# ESP32-S31 register map
Vendor: ESPRESSIF SYSTEMS (SHANGHAI) CO., LTD.; Series: ESP32 S-Series; File version: 1
CPU: RV32IMAFC r0p0, little endian, no MPU, FPU, 0 interrupt priority bits
Address unit: 32 bits
Registers are 32-bit, read-write, reset 0x0 unless marked. A register's access mark holds for its fields unless they carry their own. Offsets are from the block's base; [hi:lo] are bit positions; lines under a group give offsets from that group.

## GMAC (part 2 of 6) — GMAC Peripheral
Base 0x20350000
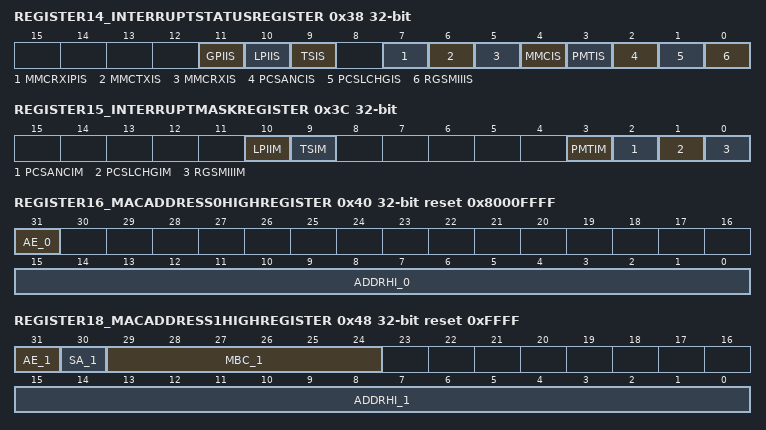
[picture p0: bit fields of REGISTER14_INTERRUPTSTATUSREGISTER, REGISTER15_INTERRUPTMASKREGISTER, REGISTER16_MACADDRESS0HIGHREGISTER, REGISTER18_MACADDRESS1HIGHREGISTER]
0x38 REGISTER14_INTERRUPTSTATUSREGISTER ro — Contains the interrupt status
  [11] GPIIS — GPI Interrupt Status When the GPIO feature is enabled, this bit is set when any active event _LL or LH_ occurs on the GPIS field _Bits [3:0]_ of Register 56 _General Purpose IO Register_ and the corresponding GPIE bit is enabled This bit is cleared on reading lane 0 _GPIS_ of Register 56 _General Purpose IO Register_ When the GPIO feature is not enabled, this bit is reserved
  [10] LPIIS — LPI Interrupt Status When the Energy Efficient Ethernet feature is enabled, this bit is set for any LPI state entry or exit in the MAC Transmitter or Receiver This bit is cleared on reading Bit 0 of Register 12 _LPI Control and Status Register_ In all other modes, this bit is reserved
  [9] TSIS — Timestamp Interrupt Status When the Advanced Timestamp feature is enabled, this bit is set when R_SS_RC any of the following conditions is true: The system time value equals or exceeds the value specified in the Target Time High and Low registers There is an overflow in the seconds register The Auxiliary snapshot trigger is asserted This bit is cleared on reading Bit 0 of Register 458 _Timestamp Status Register_ If default Timestamping is enabled, when set, this bit indicates that the system time value is equal to or exceeds the value specified in the Target Time registers In this mode, this bit is cleared after the completion of the read of this bit In all other modes, this bit is reserved
  [7] MMCRXIPIS — MMC Receive Checksum Offload Interrupt Status This bit is set high when an interrupt is generated in the MMC Receive Checksum Offload Interrupt Register This bit is cleared when all the bits in this interrupt register are cleared This bit is valid only when you select the optional MMC module and Checksum Offload Engine _Type 2_ during core configuration
  [6] MMCTXIS — MMC Transmit Interrupt Status This bit is set high when an interrupt is generated in the MMC Transmit Interrupt Register This bit is cleared when all the bits in this interrupt register are cleared This bit is valid only when you select the optional MMC module during core configuration
  [5] MMCRXIS — MMC Receive Interrupt Status This bit is set high when an interrupt is generated in the MMC Receive Interrupt Register This bit is cleared when all the bits in this interrupt register are cleared This bit is valid only when you select the optional MMC module during core configuration
  [4] MMCIS — MMC Interrupt Status This bit is set high when any of the Bits [7:5] is set high and cleared only when all of these bits are low This bit is valid only when you select the optional MMC module during core configuration
  [3] PMTIS — PMT Interrupt Status This bit is set when a magic packet or remote wakeup frame is received in the powerdown mode _see Bits 5 and 6 in the PMT Control and Status Register_ This bit is cleared when both Bits[6:5] are cleared because of a read operation to the PMT Control and Status register This bit is valid only when you select the optional PMT module during core configuration
  [2] PCSANCIS — PCS AutoNegotiation Complete This bit is set when the Autonegotiation is completed in the TBI, RTBI, or SGMII PHY interface _Bit 5 in Register 49 _AN Status Register__ This bit is cleared when you perform a read operation to the AN Status register This bit is valid only when you select the optional TBI, RTBI, or SGMII PHY interface during core configuration and operation
  [1] PCSLCHGIS — PCS Link Status Changed This bit is set because of any change in Link Status in the TBI, RTBI, or SGMII PHY interface _Bit 2 in Register 49 _AN Status Register__ This bit is cleared when you perform a read operation on the AN Status register This bit is valid only when you select the optional TBI, RTBI, or SGMII PHY interface during core configuration and operation
  [0] RGSMIIIS — RGMII or SMII Interrupt Status This bit is set because of any change in value of the Link Status of RGMII or SMII interface _Bit 3 in Register 54 _SGMII/RGMII/SMII Control and Status Register__ This bit is cleared when you perform a read operation on the SGMII/RGMII/SMII Control and Status Register This bit is valid only when you select the optional RGMII or SMII PHY interface during core configuration and operation
0x3C REGISTER15_INTERRUPTMASKREGISTER — Contains the masks for generating the interrupts
  [10] LPIIM — LPI Interrupt Mask When set, this bit disables the assertion of the interrupt signal because of the setting of the LPI Interrupt Status bit in Register 14 _Interrupt Status Register_ This bit is valid only when you select the Energy Efficient Ethernet feature during core configuration In all other modes, this bit is reserved
  [9] TSIM — Timestamp Interrupt Mask When set, this bit disables the assertion of the interrupt signal because of the setting of Timestamp Interrupt Status bit in Register 14 _Interrupt Status Register_ This bit is valid only when IEEE1588 timestamping is enabled In all other modes, this bit is reserved
  [3] PMTIM — PMT Interrupt Mask When set, this bit disables the assertion of the interrupt signal because of the setting of PMT Interrupt Status bit in Register 14 _Interrupt Status Register_
  [2] PCSANCIM — PCS AN Completion Interrupt Mask When set, this bit disables the assertion of the interrupt signal because of the setting of PCS Autonegotiation complete bit in Register 14 _Interrupt Status Register_
  [1] PCSLCHGIM — PCS Link Status Interrupt Mask When set, this bit disables the assertion of the interrupt signal because of the setting of the PCS Linkstatus changed bit in Register 14 _Interrupt Status Register_
  [0] RGSMIIIM — RGMII or SMII Interrupt Mask When set, this bit disables the assertion of the interrupt signal because of the setting of the RGMII or SMII Interrupt Status bit in Register 14 _Interrupt Status Register_
0x40 REGISTER16_MACADDRESS0HIGHREGISTER access per field reset 0x8000FFFF — Contains the higher 16 bits of the first MAC address
  [31] AE_0 ro — Address Enable This bit is always set to 1
  [15:0] ADDRHI_0 rw — MAC Address0 [47:32] This field contains the upper 16 bits _47:32_ of the first 6byte MAC address The MAC uses this field for filtering the received frames and inserting the MAC address in the Transmit Flow Control _Pause_ Frames
0x44 REGISTER17_MACADDRESS0LOWREGISTER reset 0xFFFFFFFF — Contains the lower 32 bits of the first MAC address
  [31:0] ADDRLO_0 — MAC Address0 [31:0] This field contains the lower 32 bits of the first 6byte MAC address This is used by the MAC for filtering the received frames and inserting the MAC address in the Transmit Flow Control _Pause_ Frames
0x48 REGISTER18_MACADDRESS1HIGHREGISTER reset 0xFFFF — Contains the higher 16 bits of the second MAC address This register is present only when Enable MAC Address1 is selected in coreConsultant _See Table 78_
  [31] AE_1 — Address Enable
  [30] SA_1 — Source Address When this bit is set, the MAC Address1[47:0] is used to compare with the SA fields of the received frame When this bit is reset, the MAC Address1[47:0] is used to compare with the DA fields of the received frame
  [29:24] MBC_1 — Mask Byte Control These bits are mask control bits for comparison of each of the MAC Address bytes When set high, the MAC does not compare the corresponding byte of received DA or SA with the contents of MAC Address1 registers Each bit controls the masking of the bytes as follows: Bit 29: Register 18[15:8] Bit 28: Register 18[7:0] Bit 27: Register 19[31:24] Bit 24: Register 19[7:0] You can filter a group of addresses _known as group address filtering_ by masking one or more bytes of the address
  [15:0] ADDRHI_1 — MAC Address1 [47:32] This field contains the upper 16 bits _47:32_ of the second 6byte MAC address
0x4C REGISTER19_MACADDRESS1LOWREGISTER reset 0xFFFFFFFF — Contains the lower 32 bits of the second MAC address This register is present only when Enable MAC Address1 is selected in coreConsultant _See Table 78_
  [31:0] ADDRLO_1 — MAC Address1 [31:0] This field contains the lower 32 bits of the second 6byte MAC address The content of this field is undefined until loaded by the Application after the initialization process
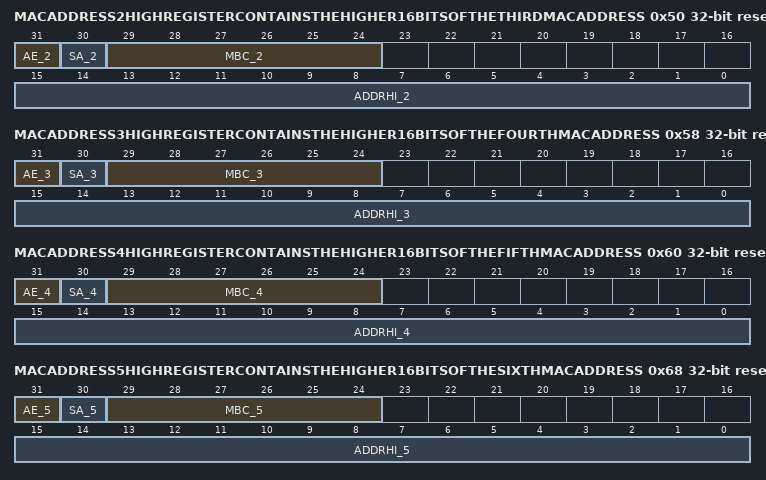
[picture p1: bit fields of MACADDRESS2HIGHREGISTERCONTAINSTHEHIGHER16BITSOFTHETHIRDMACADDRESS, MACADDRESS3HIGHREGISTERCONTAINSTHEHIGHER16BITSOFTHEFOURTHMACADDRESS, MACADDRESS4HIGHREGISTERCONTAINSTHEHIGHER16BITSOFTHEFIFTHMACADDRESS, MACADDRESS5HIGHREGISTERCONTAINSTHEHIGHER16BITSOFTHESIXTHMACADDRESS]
0x50 MACADDRESS2HIGHREGISTERCONTAINSTHEHIGHER16BITSOFTHETHIRDMACADDRESS reset 0xFFFF — Reserved
  [31] AE_2 — This register is present only when Enable MAC Address2 is selected in coreConsultant _See Table 78_
  [30] SA_2 — This register is present only when Enable MAC Address2 is selected in coreConsultant _See Table 78_
  [29:24] MBC_2 — This register is present only when Enable MAC Address2 is selected in coreConsultant _See Table 78_
  [15:0] ADDRHI_2 — This register is present only when Enable MAC Address2 is selected in coreConsultant _See Table 78_
0x54 MACADDRESS2LOWREGISTERCONTAINSTHELOWER32BITSOFTHETHIRDMACADDRESS reset 0xFFFFFFFF — Reserved
  [31:0] ADDRLO_2 — This register is present only when Enable MAC Address2 is selected in coreConsultant _See Table 78_
0x58 MACADDRESS3HIGHREGISTERCONTAINSTHEHIGHER16BITSOFTHEFOURTHMACADDRESS reset 0xFFFF — Reserved
  [31] AE_3 — This register is present only when Enable MAC Address3 is selected in coreConsultant _See Table 78_
  [30] SA_3 — This register is present only when Enable MAC Address3 is selected in coreConsultant _See Table 78_
  [29:24] MBC_3 — This register is present only when Enable MAC Address3 is selected in coreConsultant _See Table 78_
  [15:0] ADDRHI_3 — This register is present only when Enable MAC Address3 is selected in coreConsultant _See Table 78_
0x5C MACADDRESS3LOWREGISTERCONTAINSTHELOWER32BITSOFTHEFOURTHMACADDRESS reset 0xFFFFFFFF — Reserved
  [31:0] ADDRLO_3 — This register is present only when Enable MAC Address3 is selected in coreConsultant _See Table 78_
0x60 MACADDRESS4HIGHREGISTERCONTAINSTHEHIGHER16BITSOFTHEFIFTHMACADDRESS reset 0xFFFF — Reserved
  [31] AE_4 — This register is present only when Enable MAC Address4 is selected in coreConsultant _See Table 78_
  [30] SA_4 — This register is present only when Enable MAC Address4 is selected in coreConsultant _See Table 78_
  [29:24] MBC_4 — This register is present only when Enable MAC Address4 is selected in coreConsultant _See Table 78_
  [15:0] ADDRHI_4 — This register is present only when Enable MAC Address4 is selected in coreConsultant _See Table 78_
0x64 MACADDRESS4LOWREGISTERCONTAINSTHELOWER32BITSOFTHEFIFTHMACADDRESS reset 0xFFFFFFFF — Reserved
  [31:0] ADDRLO_4 — This register is present only when Enable MAC Address4 is selected in coreConsultant _See Table 78_
0x68 MACADDRESS5HIGHREGISTERCONTAINSTHEHIGHER16BITSOFTHESIXTHMACADDRESS reset 0xFFFF — Reserved
  [31] AE_5 — This register is present only when Enable MAC Address5 is selected in coreConsultant _See Table 78_
  [30] SA_5 — This register is present only when Enable MAC Address5 is selected in coreConsultant _See Table 78_
  [29:24] MBC_5 — This register is present only when Enable MAC Address5 is selected in coreConsultant _See Table 78_
  [15:0] ADDRHI_5 — This register is present only when Enable MAC Address5 is selected in coreConsultant _See Table 78_
0x6C MACADDRESS5LOWREGISTERCONTAINSTHELOWER32BITSOFTHESIXTHMACADDRESS reset 0xFFFFFFFF — Reserved
  [31:0] ADDRLO_5 — This register is present only when Enable MAC Address5 is selected in coreConsultant _See Table 78_
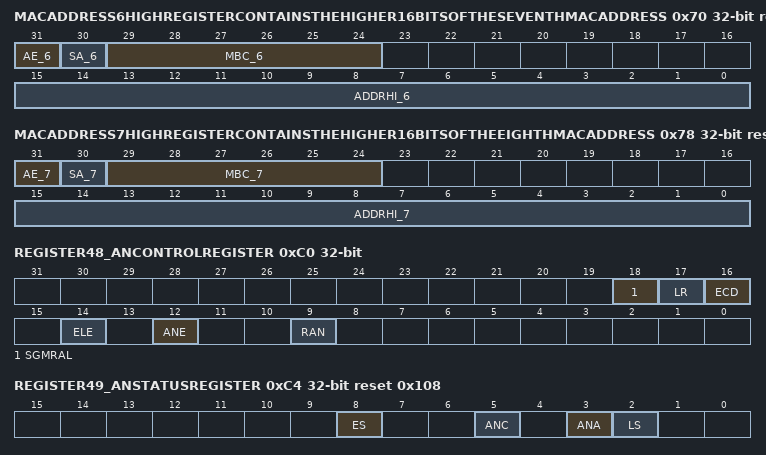
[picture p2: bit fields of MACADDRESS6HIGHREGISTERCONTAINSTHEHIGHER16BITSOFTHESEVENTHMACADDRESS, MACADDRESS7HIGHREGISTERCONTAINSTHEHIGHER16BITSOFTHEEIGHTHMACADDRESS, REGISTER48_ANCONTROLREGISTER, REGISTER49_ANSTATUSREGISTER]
0x70 MACADDRESS6HIGHREGISTERCONTAINSTHEHIGHER16BITSOFTHESEVENTHMACADDRESS reset 0xFFFF — Reserved
  [31] AE_6 — This register is present only when Enable MAC Address6 is selected in coreConsultant _See Table 78_
  [30] SA_6 — This register is present only when Enable MAC Address6 is selected in coreConsultant _See Table 78_
  [29:24] MBC_6 — This register is present only when Enable MAC Address6 is selected in coreConsultant _See Table 78_
  [15:0] ADDRHI_6 — This register is present only when Enable MAC Address6 is selected in coreConsultant _See Table 78_
0x74 MACADDRESS6LOWREGISTERCONTAINSTHELOWER32BITSOFTHESEVENTHMACADDRESS reset 0xFFFFFFFF — Reserved
  [31:0] ADDRLO_6 — This register is present only when Enable MAC Address6 is selected in coreConsultant _See Table 78_
0x78 MACADDRESS7HIGHREGISTERCONTAINSTHEHIGHER16BITSOFTHEEIGHTHMACADDRESS reset 0xFFFF — Reserved
  [31] AE_7 — This register is present only when Enable MAC Address7 is selected in coreConsultant _See Table 78_
  [30] SA_7 — This register is present only when Enable MAC Address7 is selected in coreConsultant _See Table 78_
  [29:24] MBC_7 — This register is present only when Enable MAC Address7 is selected in coreConsultant _See Table 78_
  [15:0] ADDRHI_7 — This register is present only when Enable MAC Address7 is selected in coreConsultant _See Table 78_
0x7C MACADDRESS7LOWREGISTERCONTAINSTHELOWER32BITSOFTHEEIGHTHMACADDRESS reset 0xFFFFFFFF — Reserved
  [31:0] ADDRLO_7 — This register is present only when Enable MAC Address7 is selected in coreConsultant _See Table 78_
0xC0 REGISTER48_ANCONTROLREGISTER — Enables and/or restarts autonegotiation This register also enables the Physical Coding Sublayer _PCS_ loopback This register is present only when you select the TBI, RTBI, or SGMII interface in coreConsultant
  [18] SGMRAL — SGMII RAL Control When set, this bit forces the SGMII RAL block to operate in the speed configured in the Speed and Port Select bits of the MAC Configuration register This is useful when the SGMII interface is used in a direct MAC to MAC connection _without a PHY_ and any MAC must reconfigure the speed When reset, the SGMII RAL block operates according to the link speed status received on SGMII _from the PHY_ This bit is reserved _and RO_ if the SGMII PHY interface is not selected during core configuration
  [17] LR — Lock to Reference When set, this bit enables the PHY to lock its PLL to the 125 MHz reference clock This bit controls the pcs_lck_ref_o signal on the TBI, RTBI, or SGMII interface
  [16] ECD — Enable Comma Detect When set, this bit enables the PHY for comma detection and word resynchronization This bit controls the pcs_en_cdet_o signal on the TBI, RTBI, or SGMII interface
  [14] ELE — External Loopback Enable When set, this bit causes the PHY to loopback the transmit data into the receive path The pcs_ewrap_o signal is asserted high when this bit is set
  [12] ANE — AutoNegotiation Enable When set, this bit enables the MAC to perform autonegotiation with the link partner Clearing this bit disables the autonegotiation
  [9] RAN — Restart AutoNegotiation When set, this bit causes autonegotiation to restart if Bit 12 _ANE_ is set This bit is selfclearing after autonegotiation starts This bit should be cleared for normal operation
0xC4 REGISTER49_ANSTATUSREGISTER ro reset 0x108 — Indicates the link and autonegotiation status This register is present only when you select the TBI, RTBI, or SGMII interface in coreConsultant
  [8] ES — Extended Status This bit is tied to high if the TBI or RTBI interface is selected during core configuration indicating that the MAC supports extended status information in Register 53 _TBI Extended Status Register_ This bit is tied to low if the SGMII interface is selected and the TBI or RTBI interface is not selected during core configuration indicating that Register 53 is not present
  [5] ANC — AutoNegotiation Complete When set, this bit indicates that the autonegotiation process is complete This bit is cleared when autonegotiation is reinitiated
  [3] ANA — AutoNegotiation Ability This bit is always high because the MAC supports auto negotiation
  [2] LS — Link Status This bit indicates whether the data channel _link_ is up or down For the TBI, RTBI or SGMII interfaces, if ANEG is going on, data cannot be transferred across the link and hence the link is given as down
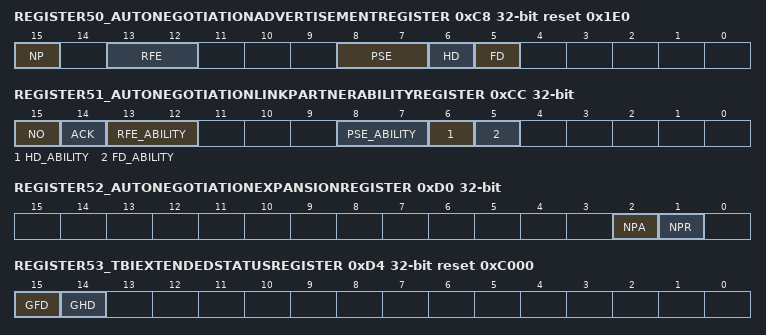
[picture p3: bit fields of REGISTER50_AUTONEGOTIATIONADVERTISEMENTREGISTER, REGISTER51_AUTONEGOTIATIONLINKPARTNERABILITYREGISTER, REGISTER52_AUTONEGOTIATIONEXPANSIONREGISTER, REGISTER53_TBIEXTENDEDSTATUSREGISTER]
0xC8 REGISTER50_AUTONEGOTIATIONADVERTISEMENTREGISTER access per field reset 0x1E0 — This register is configured before autonegotiation begins It contains the advertised ability of the MAC This register is present only when you select the TBI or RTBI interface in coreConsultant
  [15] NP ro — Next Page Support This bit is always low because the MAC does not support the next page
  [13:12] RFE rw — Remote Fault Encoding These bits provide a remote fault encoding, indicating to a link partner that a fault or error condition has occurred The encoding of these bits is defined in IEEE 8023z, Section 37215
  [8:7] PSE rw — Pause Encoding These bits provide an encoding for the Pause bits, indicating that the MAC is capable of configuring the Pause function as defined in IEEE 8023x The encoding of these bits is defined in IEEE 8023z, Section 37214
  [6] HD rw — HalfDuplex When set high, this bit indicates that the MAC supports the halfduplex mode This bit is always low _and RO_ when the MAC is configured for the fullduplexonly mode
  [5] FD rw — FullDuplex When set high, this bit indicates that the MAC supports the fullduplex mode
0xCC REGISTER51_AUTONEGOTIATIONLINKPARTNERABILITYREGISTER ro — Contains the advertised ability of the link partner Its value is valid after successful completion of autonegotiation or when a new base page has been received _indicated in the AutoNegotiation Expansion Register_ This register is present only when you select the TBI or RTBI interface in coreConsultant
  [15] NO — Next Page Support When set, this bit indicates that more next page information is available When cleared, this bit indicates that next page exchange is not desired
  [14] ACK — Acknowledge When set, the autonegotiation function uses this bit to indicate that the link partner has successfully received the base page of the MAC When cleared, it indicates that the link partner did not successfully receive the base page of the MAC
  [13:12] RFE_ABILITY — Remote Fault Encoding These bits provide a remote fault encoding, indicating a fault or error condition of the link partner The encoding of these bits is defined in IEEE 8023z, Section 37215
  [8:7] PSE_ABILITY — Pause Encoding These bits provide an encoding for the Pause bits, indicating that the link partner's capability of configuring the Pause function as defined in the IEEE 8023x specification The encoding of these bits is defined in IEEE 8023z, Section 37214
  [6] HD_ABILITY — HalfDuplex When set, this bit indicates that the link partner has the ability to operate in the halfduplex mode When cleared, this bit indicates that the link partner does not have the ability to operate in the halfduplex mode
  [5] FD_ABILITY — FullDuplex When set, this bit indicates that the link partner has the ability to operate in the full duplex mode When cleared, this bit indicates that the link partner does not have the ability to operate in the fullduplex mode
0xD0 REGISTER52_AUTONEGOTIATIONEXPANSIONREGISTER ro — Indicates whether a new base page has been received from the link partner This register is present only when you select the TBI or RTBI interface in coreConsultant
  [2] NPA — Next Page Ability This bit is always low because the MAC does not support the next page function
  [1] NPR — New Page Received When set, this bit indicates that the MAC has received a new page This bit is cleared when read
0xD4 REGISTER53_TBIEXTENDEDSTATUSREGISTER ro reset 0xC000 — Indicates all modes of operation of the MAC This register is present only when you select the TBI or RTBI interface in coreConsultant
  [15] GFD — 1000BASEX FullDuplex Capable This bit indicates that the MAC is able to perform the fullduplex and 1000BASEX operations
  [14] GHD — 1000BASEX HalfDuplex Capable This bit indicates that the MAC is able to perform the halfduplex and 1000BASEX operations This bit is always low when the MAC is configured for the fullduplexonly operation during core configuration
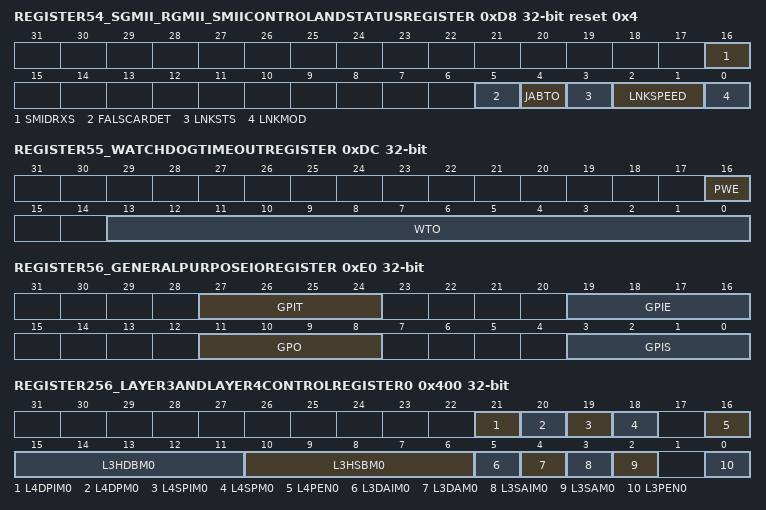
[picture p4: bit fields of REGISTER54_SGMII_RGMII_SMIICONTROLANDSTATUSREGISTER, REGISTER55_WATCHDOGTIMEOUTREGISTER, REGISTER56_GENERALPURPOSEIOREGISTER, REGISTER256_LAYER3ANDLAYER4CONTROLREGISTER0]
0xD8 REGISTER54_SGMII_RGMII_SMIICONTROLANDSTATUSREGISTER access per field reset 0x4 — Indicates the status signals received from the PHY through the SGMII, RGMII, or SMII interface This register is present only when you select the SGMII, RGMII, or SMII interface in coreConsultant
  [16] SMIDRXS rw — Delay SMII RX Data Sampling with respect to the SMII SYNC Signal When set, the first bit of the SMII RX data is sampled one cycle after the SMII SYNC signal When reset, the first bit of the SMII RX data is sampled along with the SMII SYNC signal If the SMII PHY Interface with source synchronous mode is selected during core configuration, this bit is reserved _RO with default value_
  [5] FALSCARDET ro — False Carrier Detected This bit indicates whether the SMII PHY detected false carrier _1'b1_ This bit is reserved when the MAC is configured for the SGMII or RGMII PHY interface
  [4] JABTO ro — Jabber Timeout This bit indicates whether there is jabber timeout error _1'b1_ in the received frame This bit is reserved when the MAC is configured for the SGMII or RGMII PHY interface
  [3] LNKSTS ro — Link Status This bit indicates whether the link between the local PHY and the remote PHY is up or down It gives the status of the link between the SGMII of MAC and the SGMII of the local PHY The status bits are received from the local PHY during ANEG betweent he MAC and PHY on the SGMII link
  [2:1] LNKSPEED ro — Link Speed
  [0] LNKMOD ro — Link Mode This bit indicates the current mode of operation of the link: 1’b0: Halfduplex mode 1’b1: Fullduplex mode
0xDC REGISTER55_WATCHDOGTIMEOUTREGISTER — Controls the watchdog timeout for received frames
  [16] PWE — Programmable Watchdog Enable When this bit is set and Bit 23 _WD_ of Register 0 _MAC Configuration Register_ is reset, the WTO field _Bits[13:0]_ is used as watchdog timeout for a received frame When this bit is cleared, the watchdog timeout for a received frame is controlled by the setting of Bit 23 _WD_ and Bit 20 _JE_ in Register 0 _MAC Configuration Register_
  [13:0] WTO — Watchdog Timeout When Bit 16 _PWE_ is set and Bit 23 _WD_ of Register 0 _MAC Configuration Register_ is reset, this field is used as watchdog timeout for a received frame If the length of a received frame exceeds the value of this field, such frame is terminated and declared as an error frame Note: When Bit 16 _PWE_ is set, the value in this field should be more than 1,522 _0x05F2_ Otherwise, the IEEE Std 8023specified valid tagged frames are declared as error frames and are dropped
0xE0 REGISTER56_GENERALPURPOSEIOREGISTER — Provides the control to drive up to 4 bits of output ports _GPO_ and also provides the status of up to 4 input ports _GPIS_
  [27:24] GPIT — GPI Type When set, this bit indicates that the corresponding GPIS is of latchedlow _LL_ type When reset, this bit indicates that the corresponding GPIS is of latchedhigh _LH_ type The number of bits available in this field depend on the GP Input Signal Width option Other bits are not used _reserved and always reset_
  [19:16] GPIE — GPI Interrupt Enable When this bit is set and the programmed event _LL or LH_ occurs on the corresponding GPIS bit, Bit 11 _GPIIS_ of Register 14 _Interrupt Status Register_ is set Accordingly, the interrupt is generated on the mci_intr_o or sbd_intr_o The GPIIS bit is cleared when the host reads the Bits[7:0] of this register When reset, Bit 11 _GPIIS_ of Register 14 _Interrupt Status Register_ is not set when any event occurs on the corresponding GPIS bits The number of bits available in this field depend on the GP Input Signal Width option Other bits are not used _reserved and always reset_
  [11:8] GPO — General Purpose Output When this bit is set, it directly drives the gpo_o output ports When this bit is reset, it does not directly drive the gpo_o output ports The number of bits available in this field depend on the GP Output Signal Width option Other bits are not used _reserved and always reset_
  [3:0] GPIS — General Purpose Input Status This field gives the status of the signals connected to the gpi_i input ports This field is of the following types based on the setting of the corresponding GPIT field of this register: Latchedlow _LL_: This field is cleared when the corresponding gpi_i input becomes low This field remains low until the host reads this field After this, this field reflects the current value of the gpi_i input Latchedhigh _LH_: This field is set when the corresponding gpi_i input becomes high This field remains high until the host reads this field After this, this field reflects the current value of the gpi_i input The number of bits available in this field depend on the GP Input Signal Width option Other bits are not used _reserved and always reset_
0x400 REGISTER256_LAYER3ANDLAYER4CONTROLREGISTER0 — Controls the operations of the Layer 3 and Layer 4 frame filtering
  [21] L4DPIM0 — Layer 4 Destination Port Inverse Match Enable When set, this bit indicates that the Layer 4 Destination Port number field is enabled for inverse matching When reset, this bit indicates that the Layer 4 Destination Port number field is enabled for perfect matching This bit is valid and applicable only when Bit 20 _L4DPM0_ is set high
  [20] L4DPM0 — Layer 4 Destination Port Match Enable When set, this bit indicates that the Layer 4 Destination Port number field is enabled for matching When reset, the MAC ignores the Layer 4 Destination Port number field for matching
  [19] L4SPIM0 — Layer 4 Source Port Inverse Match Enable When set, this bit indicates that the Layer 4 Source Port number field is enabled for inverse matching When reset, this bit indicates that the Layer 4 Source Port number field is enabled for perfect matching This bit is valid and applicable only when Bit 18 _L4SPM0_ is set high
  [18] L4SPM0 — Layer 4 Source Port Match Enable When set, this bit indicates that the Layer 4 Source Port number field is enabled for matching When reset, the MAC ignores the Layer 4 Source Port number field for matching
  [16] L4PEN0 — Layer 4 Protocol Enable When set, this bit indicates that the Source and Destination Port number fields for UDP frames are used for matching When reset, this bit indicates that the Source and Destination Port number fields for TCP frames are used for matching The Layer 4 matching is done only when either L4SPM0 or L4DPM0 bit is set high
  [15:11] L3HDBM0 — Layer 3 IP DA Higher Bits Match IPv4 Frames: This field contains the number of higher bits of IP Destination Address that are matched in the IPv4 frames The following list describes the values of this field: 0: No bits are masked 1: LSb[0] is masked 2: Two LSbs [1:0] are masked 31: All bits except MSb are masked IPv6 Frames: Bits [12:11] of this field correspond to Bits [6:5] of L3HSBM0, which indicate the number of lower bits of IP Source or Destination Address that are masked in the IPv6 frames The following list describes the concatenated values of the L3HDBM0[1:0] and L3HSBM0 bits: 0: No bits are masked 1: LSb[0] is masked 2: Two LSbs [1:0] are masked … 127: All bits except MSb are masked This field is valid and applicable only if L3DAM0 or L3SAM0 is set high
  [10:6] L3HSBM0 — Layer 3 IP SA Higher Bits Match IPv4 Frames: This field contains the number of lower bits of IP Source Address that are masked for matching in the IPv4 frames The following list describes the values of this field: 0: No bits are masked 1: LSb[0] is masked 2: Two LSbs [1:0] are masked 31: All bits except MSb are masked IPv6 Frames: This field contains Bits [4:0] of the field that indicates the number of higher bits of IP Source or Destination Address matched in the IPv6 frames This field is valid and applicable only if L3DAM0 or L3SAM0 is set high
  [5] L3DAIM0 — Layer 3 IP DA Inverse Match Enable When set, this bit indicates that the Layer 3 IP Destination Address field is enabled for inverse matching When reset, this bit indicates that the Layer 3 IP Destination Address field is enabled for perfect matching This bit is valid and applicable only when Bit 4 _L3DAM0_ is set high
  [4] L3DAM0 — Layer 3 IP DA Match Enable When set, this bit indicates that Layer 3 IP Destination Address field is enabled for matching When reset, the MAC ignores the Layer 3 IP Destination Address field for matching Note: When Bit 0 _L3PEN0_ is set, you should set either this bit or Bit 2 _L3SAM0_ because either IPv6 DA or SA can be checked for filtering
  [3] L3SAIM0 — Layer 3 IP SA Inverse Match Enable When set, this bit indicates that the Layer 3 IP Source Address field is enabled for inverse matching When reset, this bit indicates that the Layer 3 IP Source Address field is enabled for perfect matching This bit is valid and applicable only when Bit 2 _L3SAM0_ is set high
  [2] L3SAM0 — Layer 3 IP SA Match Enable When set, this bit indicates that the Layer 3 IP Source Address field is enabled for matching When reset, the MAC ignores the Layer 3 IP Source Address field for matching Note: When Bit 0 _L3PEN0_ is set, you should set either this bit or Bit 4 _L3DAM0_ because either IPv6 SA or DA can be checked for filtering
  [0] L3PEN0 — Layer 3 Protocol Enable When set, this bit indicates that the Layer 3 IP Source or Destination Address matching is enabled for the IPv6 frames When reset, this bit indicates that the Layer 3 IP Source or Destination Address matching is enabled for the IPv4 frames The Layer 3 matching is done only when either L3SAM0 or L3DAM0 bit is set high
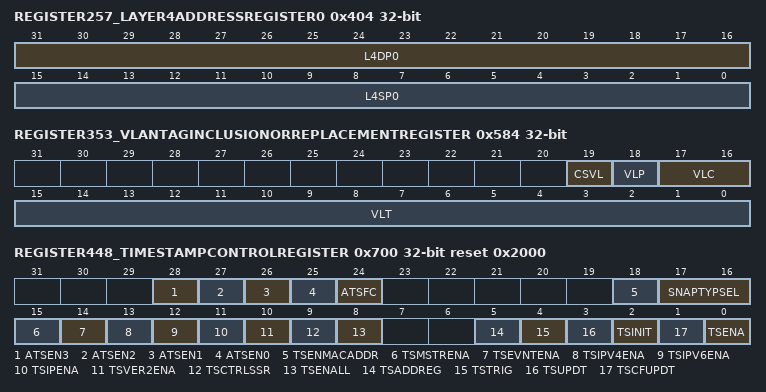
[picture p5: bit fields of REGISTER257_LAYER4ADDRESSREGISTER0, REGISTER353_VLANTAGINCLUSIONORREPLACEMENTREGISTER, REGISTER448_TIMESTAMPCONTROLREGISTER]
0x404 REGISTER257_LAYER4ADDRESSREGISTER0 — Layer 4 Port number field It contains the 16bit Source and Destination Port numbers of the TCP or UDP frame
  [31:16] L4DP0 — Layer 4 Destination Port Number Field When Bit 16 _L4PEN0_ is reset and Bit 20 _L4DPM0_ is set in Register 256 _Layer 3 and Layer 4 Control Register 0_, this field contains the value to be matched with the TCP Destination Port Number field in the IPv4 or IPv6 frames When Bit 16 _L4PEN0_ and Bit 20 _L4DPM0_ are set in Register 256 _Layer 3 and Layer 4 Control Register 0_, this field contains the value to be matched with the UDP Destination Port Number field in the IPv4 or IPv6 frames
  [15:0] L4SP0 — Layer 4 Source Port Number Field When Bit 16 _L4PEN0_ is reset and Bit 20 _L4DPM0_ is set in Register 256 _Layer 3 and Layer 4 Control Register 0_, this field contains the value to be matched with the TCP Source Port Number field in the IPv4 or IPv6 frames When Bit 16 _L4PEN0_ and Bit 20 _L4DPM0_ are set in Register 256 _Layer 3 and Layer 4 Control Register 0_, this field contains the value to be matched with the UDP Source Port Number field in the IPv4 or IPv6 frames
0x410 REGISTER260_LAYER3ADDRESS0REGISTER0 — Layer 3 Address field For IPv4 frames, it contains the 32bit IP Source Address field For IPv6 frames, it contains Bits [31:0] of the 128bit IP Source Address or Destination Address field
  [31:0] L3A00 — Layer 3 Address 0 Field When Bit 0 _L3PEN0_ and Bit 2 _L3SAM0_ are set in Register 256 _Layer 3 and Layer 4 Control Register 0_, this field contains the value to be matched with Bits [31:0] of the IP Source Address field in the IPv6 frames When Bit 0 _L3PEN0_ and Bit 4 _L3DAM0_ are set in Register 256 _Layer 3 and Layer 4 Control Register 0_, this field contains the value to be matched with Bits [31:0] of the IP Destination Address field in the IPv6 frames When Bit 0 _L3PEN0_ is reset and Bit 2 _L3SAM0_ is set in Register 256 _Layer 3 and Layer 4 Control Register 0_, this field contains the value to be matched with the IP Source Address field in the IPv4 frames
0x414 REGISTER261_LAYER3ADDRESS1REGISTER0 — Layer 3 Address 1 field For IPv4 frames, it contains the 32bit IP Destination Address field For IPv6 frames, it contains Bits [63:32] of the 128bit IP Source Address or Destination Address field
  [31:0] L3A10 — Layer 3 Address 1 Field When Bit 0 _L3PEN0_ and Bit 2 _L3SAM0_ are set in Register 256 _Layer 3 and Layer 4 Control Register 0_, this field contains the value to be matched with Bits [63:32] of the IP Source Address field in the IPv6 frames When Bit 0 _L3PEN0_ and Bit 4 _L3DAM0_ are set in Register 256 _Layer 3 and Layer 4 Control Register 0_, this field contains the value to be matched with Bits [63:32] of the IP Destination Address field in the IPv6 frames When Bit 0 _L3PEN0_ is reset and Bit 4 _L3DAM0_ is set in Register 256 _Layer 3 and Layer 4 Control Register 0_, this field contains the value to be matched with the IP Destination Address field in the IPv4 frames
0x418 REGISTER262_LAYER3ADDRESS2REGISTER0 — Layer 3 Address 2 field This register is reserved for IPv4 frames For IPv6 frames, it contains Bits [95:64] of the 128bit IP Source Address or Destination Address field
  [31:0] L3A20 — Layer 3 Address 2 Field When Bit 0 _L3PEN0_ and Bit 2 _L3SAM0_ are set in Register 256 _Layer 3 and Layer 4 Control Register 0_, this field contains the value to be matched with Bits [95:64] of the IP Source Address field in the IPv6 frames When Bit 0 _L3PEN0_ and Bit 4 _L3DAM0_ are set in Register 256 _Layer 3 and Layer 4 Control Register 0_, this field contains value to be matched with Bits [95:64] of the IP Destination Address field in the IPv6 frames When Bit 0 _L3PEN0_ is reset in Register 256 _Layer 3 and Layer 4 Control Register 0_, this register is not used
0x41C REGISTER263_LAYER3ADDRESS3REGISTER0 — Layer 3 Address 3 field This register is reserved for IPv4 frames For IPv6 frames, it contains Bits [127:96] of the 128bit IP Source Address or Destination Address field
  [31:0] L3A30 — Layer 3 Address 3 Field When Bit 0 _L3PEN0_ and Bit 2 _L3SAM0_ are set in Register 256 _Layer 3 and Layer 4 Control Register 0_, this field contains the value to be matched with Bits [127:96] of the IP Source Address field in the IPv6 frames When Bit 0 _L3PEN0_ and Bit 4 _L3DAM0_ are set in Register 256 _Layer 3 and Layer 4 Control Register 0_, this field contains the value to be matched with Bits [127:96] of the IP Destination Address field in the IPv6 frames When Bit 0 _L3PEN0_ is reset in Register 256 _Layer 3 and Layer 4 Control Register 0_, this register is not used
0x500 REGISTER320_HASHTABLEREGISTER0 — This register contains the first 32 bits of the hash table when the width of the Hash table is 128 bits or 256 bits
  [31:0] HT31T0 — First 32 bits of Hash Table This field contains the first 32 Bits _31:0_ of the Hash table Note Registers 321 through 327 are similar to Register 320 _Hash Table Register 0_ Registers 324 through 327 are present only when you select the 256bit Hash table during core configuration
0x584 REGISTER353_VLANTAGINCLUSIONORREPLACEMENTREGISTER — This register contains the VLAN tag for insertion into or replacement in the transmit frames
  [19] CSVL — CVLAN or SVLAN When this bit is set, SVLAN type _0x88A8_ is inserted or replaced in the 13th and 14th bytes of transmitted frames When this bit is reset, CVLAN type _0x8100_ is inserted or replaced in the transmitted frames
  [18] VLP — VLAN Priority Control When this bit is set, the control Bits [17:16] are used for VLAN deletion, insertion, or replacement When this bit is reset, the mti_vlan_ctrl_i control input is used, and Bits [17:16] are ignored
  [17:16] VLC — VLAN Tag Control in Transmit Frames 2’b00: No VLAN tag deletion, insertion, or replacement 2’b01: VLAN tag deletion The MAC removes the VLAN type _bytes 13 and 14_ and VLAN tag _bytes 15 and 16_ of all transmitted frames with VLAN tags 2’b10: VLAN tag insertion The MAC inserts VLT in bytes 15 and 16 of the frame after inserting the Type value _0x8100/0x88a8_ in bytes 13 and 14 This operation is performed on all transmitted frames, irrespective of whether they already have a VLAN tag 2’b11: VLAN tag replacement The MAC replaces VLT in bytes 15 and 16 of all VLANtype transmitted frames _Bytes 13 and 14 are 0x8100/0x88a8_ Note: Changes to this field take effect only on the start of a frame If you write this register field when a frame is being transmitted, only the subsequent frame can use the updated value, that is, the current frame does not use the updated value
  [15:0] VLT — VLAN Tag for Transmit Frames This field contains the value of the VLAN tag to be inserted or replaced The value must only be changed when the transmit lines are inactive or during the initialization phase Bits[15:13] are the User Priority, Bit 12 is the CFI/DEI, and Bits[11:0] are the VLAN tag’s VID field
0x588 REGISTER354_VLANHASHTABLEREGISTER — This register contains the VLAN hash table
  [15:0] VLHT — VLAN Hash Table This field contains the 16bit VLAN Hash Table
0x700 REGISTER448_TIMESTAMPCONTROLREGISTER reset 0x2000 — Controls the timestamp generation and update logic This register is present only when IEEE1588 timestamping is enabled during coreConsultant configuration
  [28] ATSEN3 — Auxiliary Snapshot 3 Enable This field controls capturing the Auxiliary Snapshot Trigger 3 When this bit is set, the Auxiliary snapshot of event on ptp_aux_trig_i[3] input is enabled When this bit is reset, the events on this input are ignored This bit is reserved when the Add IEEE 1588 Auxiliary Snapshot option is not selected during core configuration or the selected number in the Number of IEEE 1588 Auxiliary Snapshot Inputs option is less than four
  [27] ATSEN2 — Auxiliary Snapshot 2 Enable This field controls capturing the Auxiliary Snapshot Trigger 2 When this bit is set, the Auxiliary snapshot of event on ptp_aux_trig_i[2] input is enabled When this bit is reset, the events on this input are ignored This bit is reserved when the Add IEEE 1588 Auxiliary Snapshot option is not selected during core configuration or the selected number in the Number of IEEE 1588 Auxiliary Snapshot Inputs option is less than three
  [26] ATSEN1 — Auxiliary Snapshot 1 Enable This field controls capturing the Auxiliary Snapshot Trigger 1 When this bit is set, the Auxiliary snapshot of event on ptp_aux_trig_i[1] input is enabled When this bit is reset, the events on this input are ignored This bit is reserved when the Add IEEE 1588 Auxiliary Snapshot option is not selected during core configuration or the selected number in the Number of IEEE 1588 Auxiliary Snapshot Inputs option is less than two
  [25] ATSEN0 — Auxiliary Snapshot 0 Enable This field controls capturing the Auxiliary Snapshot Trigger 0 When this bit is set, the Auxiliary snapshot of event on ptp_aux_trig_i[0] input is enabled When this bit is reset, the events on this input are ignored This bit is reserved when the Add IEEE 1588 Auxiliary Snapshot option is not selected during core configuration
  [24] ATSFC — Auxiliary Snapshot FIFO Clear When set, it resets the pointers of the Auxiliary Snapshot FIFO This bit is cleared when the pointers are reset and the FIFO is empty When this bit is high, auxiliary snapshots get stored in the FIFO This bit is reserved when the Add IEEE 1588 Auxiliary Snapshot option is not selected during core configuration
  [18] TSENMACADDR — Enable MAC address for PTP Frame Filtering When set, the DA MAC address _that matches any MAC Address register_ is used to filter the PTP frames when PTP is directly sent over Ethernet
  [17:16] SNAPTYPSEL — Select PTP packets for Taking Snapshots These bits along with Bits 15 and 14 decide the set of PTP packet types for which snapshot needs to be taken The encoding is given in Table 670 on page 462
  [15] TSMSTRENA — Enable Snapshot for Messages Relevant to Master When set, the snapshot is taken only for the messages relevant to the master node Otherwise, the snapshot is taken for the messages relevant to the slave node
  [14] TSEVNTENA — Enable Timestamp Snapshot for Event Messages When set, the timestamp snapshot is taken only for event messages _SYNC, Delay_Req, Pdelay_Req, or Pdelay_Resp_ When reset, the snapshot is taken for all messages except Announce, Management, and Signaling For more information about the timestamp snapshots, see Table 670 on page 462
  [13] TSIPV4ENA — Enable Processing of PTP Frames Sent over IPv4UDP When set, the MAC receiver processes the PTP packets encapsulated in UDP over IPv4 packets When this bit is clear, the MAC ignores the PTP transported over UDPIPv4 packets This bit is set by default
  [12] TSIPV6ENA — Enable Processing of PTP Frames Sent over IPv6UDP When set, the MAC receiver processes PTP packets encapsulated in UDP over IPv6 packets When this bit is clear, the MAC ignores the PTP transported over UDPIPv6 packets
  [11] TSIPENA — Enable Processing of PTP over Ethernet Frames When set, the MAC receiver processes the PTP packets encapsulated directly in the Ethernet frames When this bit is clear, the MAC ignores the PTP over Ethernet packets
  [10] TSVER2ENA — Enable PTP packet Processing for Version 2 Format When set, the PTP packets are processed using the 1588 version 2 format Otherwise, the PTP packets are processed using the version 1 format The IEEE 1588 Version 1 and Version 2 format are described in “PTP Processing and Control” on page 155
  [9] TSCTRLSSR — Timestamp Digital or Binary Rollover Control When set, the Timestamp Low register rolls over after 0x3B9A_C9FF value _that is, 1 nanosecond accuracy_ and increments the timestamp _High_ seconds When reset, the rollover value of subsecond register is 0x7FFF_FFFF The subsecond increment has to be programmed correctly depending on the PTP reference clock frequency and the value of this bit
  [8] TSENALL — Enable Timestamp for All Frames When set, the timestamp snapshot is enabled for all frames received by the MAC
  [5] TSADDREG — Addend Reg Update When set, the content of the Timestamp Addend register is updated in the PTP block for fine correction This is cleared when the update is completed This register bit should be zero before setting it
  [4] TSTRIG — Timestamp Interrupt Trigger Enable When set, the timestamp interrupt is generated when the System Time becomes greater than the value written in the Target Time register This bit is reset after the generation of the Timestamp Trigger Interrupt
  [3] TSUPDT — Timestamp Update When set, the system time is updated _added or subtracted_ with the value specified in Register 452 _System Time Seconds Update Register_ and Register 453 _System Time Nanoseconds Update Register_ This bit should be read zero before updating it This bit is reset when the update is completed in hardware The “Timestamp Higher Word” register _if enabled during core configuration_ is not updated
  [2] TSINIT — Timestamp Initialize When set, the system time is initialized _overwritten_ with the value specified in the Register 452 _System Time Seconds Update Register_ and Register 453 _System Time Nanoseconds Update Register_ This bit should be read zero before updating it This bit is reset when the initialization is complete The “Timestamp Higher Word” register _if enabled during core configuration_ can only be initialized
  [1] TSCFUPDT — Timestamp Fine or Coarse Update When set, this bit indicates that the system times update should be done using the fine update method When reset, it indicates the system timestamp update should be done using the Coarse method
  [0] TSENA — Timestamp Enable When set, the timestamp is added for the transmit and receive frames When disabled, timestamp is not added for the transmit and receive frames and the Timestamp Generator is also suspended You need to initialize the Timestamp _system time_ after enabling this mode On the receive side, the MAC processes the 1588 frames only if this bit is set
